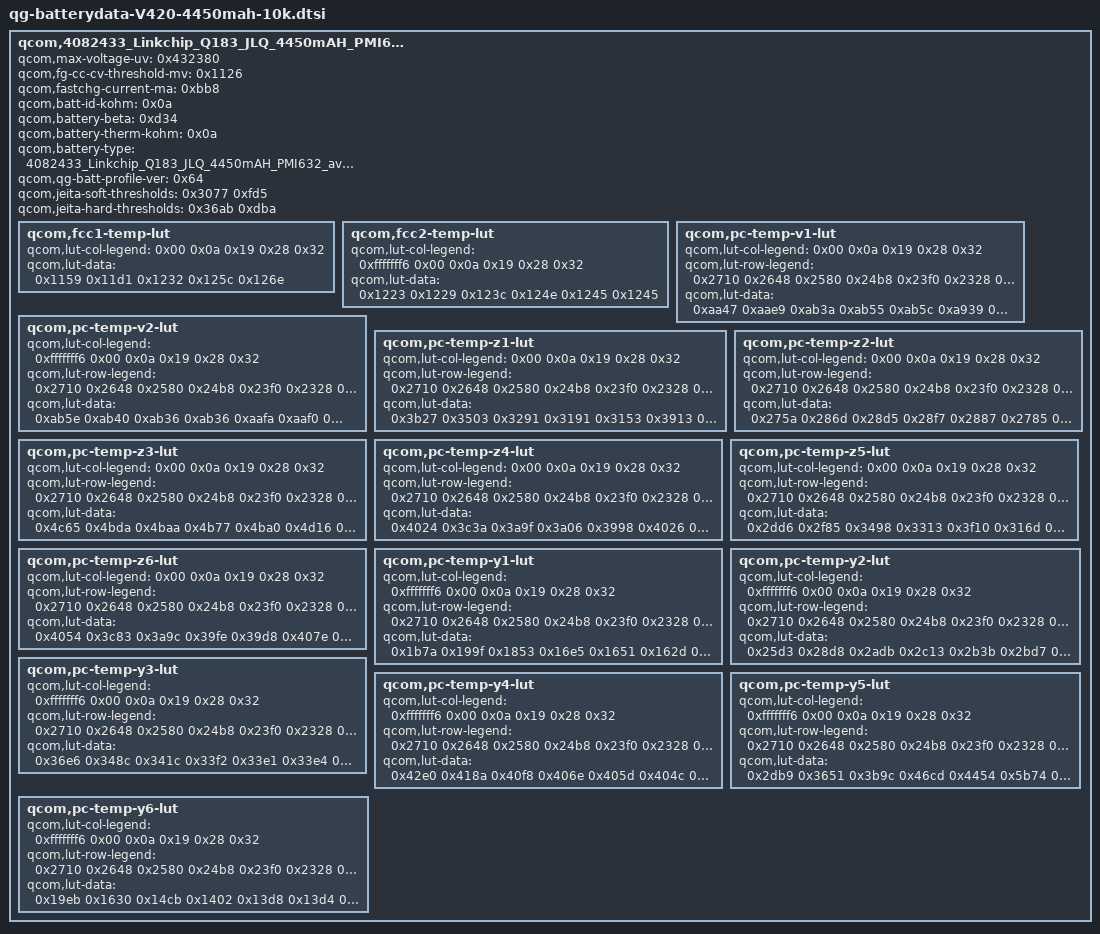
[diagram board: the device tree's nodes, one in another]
qcom,4082433_Linkchip_Q183_JLQ_4450mAH_PMI632 {
	qcom,max-voltage-uv = <0x432380>;
	qcom,fg-cc-cv-threshold-mv = <0x1126>;
	qcom,fastchg-current-ma = <0xbb8>;
	qcom,batt-id-kohm = <0x0a>;
	qcom,battery-beta = <0xd34>;
	qcom,battery-therm-kohm = <0x0a>;
	qcom,battery-type = "4082433_Linkchip_Q183_JLQ_4450mAH_PMI632_averaged_MasterSlave_Jul1th2019";
	qcom,qg-batt-profile-ver = <0x64>;
	qcom,jeita-soft-thresholds = <0x3077 0xfd5>;
	qcom,jeita-hard-thresholds = <0x36ab 0xdba>;

	qcom,fcc1-temp-lut {
		qcom,lut-col-legend = <0x00 0x0a 0x19 0x28 0x32>;
		qcom,lut-data = <0x1159 0x11d1 0x1232 0x125c 0x126e>;
	};

	qcom,fcc2-temp-lut {
		qcom,lut-col-legend = <0xfffffff6 0x00 0x0a 0x19 0x28 0x32>;
		qcom,lut-data = <0x1223 0x1229 0x123c 0x124e 0x1245 0x1245>;
	};

	qcom,pc-temp-v1-lut {
		qcom,lut-col-legend = <0x00 0x0a 0x19 0x28 0x32>;
		qcom,lut-row-legend = <0x2710 0x2648 0x2580 0x24b8 0x23f0 0x2328 0x2260 0x2198 0x20d0 0x2008 0x1f40 0x1e78 0x1db0 0x1ce8 0x1c20 0x1b58 0x1a90 0x19c8 0x1900 0x1838 0x1770 0x16a8 0x15e0 0x1518 0x1450 0x1388 0x12c0 0x11f8 0x1130 0x1068 0xfa0 0xed8 0xe10 0xd48 0xc80 0xbb8 0xaf0 0xa28 0x960 0x898 0x7d0 0x708 0x640 0x578 0x4b0 0x3e8 0x384 0x320 0x2bc 0x258 0x1f4 0x190 0x12c 0xc8 0x64 0x00>;
		qcom,lut-data = <0xaa47 0xaae9 0xab3a 0xab55 0xab5c 0xa939 0xaa1f 0xaa6d 0xaa88 0xaa8d 0xa835 0xa912 0xa98a 0xa9b1 0xa9bb 0xa73e 0xa821 0xa8a3 0xa8d3 0xa8e3 0xa652 0xa731 0xa7b3 0xa7ea 0xa7fe 0xa56e 0xa640 0xa6c3 0xa6fe 0xa715 0xa491 0xa554 0xa5d5 0xa614 0xa62a 0xa3ba 0xa470 0xa4ea 0xa52a 0xa53d 0xa2e6 0xa393 0xa403 0xa442 0xa454 0xa211 0xa2b9 0xa320 0xa35b 0xa36d 0xa149 0xa1e1 0xa23f 0xa277 0xa289 0xa09f 0xa116 0xa161 0xa196 0xa1a8 0x9ff6 0xa069 0xa090 0xa0ba 0xa0ca 0x9f12 0x9fc0 0x9fd8 0x9fe7 0x9ff6 0x9ddd 0x9edd 0x9f1e 0x9f19 0x9f29 0x9cd8 0x9db5 0x9e3d 0x9e4f 0x9e60 0x9c2a 0x9cc3 0x9d46 0x9d87 0x9d9c 0x9b9c 0x9c27 0x9c84 0x9ccb 0x9ce0 0x9b16 0x9ba3 0x9bf3 0x9c22 0x9c33 0x9a9d 0x9b1a 0x9b60 0x9b7a 0x9b88 0x9a26 0x9a94 0x9ab8 0x9abc 0x9aca 0x99ab 0x99ff 0x9a01 0x99ed 0x99f9 0x9931 0x9955 0x9923 0x9921 0x992d 0x98bc 0x98a1 0x981b 0x984d 0x9860 0x984b 0x97dd 0x9768 0x979d 0x97ae 0x97df 0x9715 0x9705 0x9726 0x9730 0x977a 0x9698 0x96b4 0x96c3 0x96c9 0x971a 0x964c 0x9660 0x9660 0x9661 0x96c1 0x9611 0x9612 0x9601 0x95fc 0x966d 0x95df 0x95ca 0x95aa 0x95a0 0x9625 0x95b5 0x9586 0x955d 0x954f 0x95ea 0x958f 0x954a 0x9518 0x9506 0x95b8 0x956d 0x9519 0x94dc 0x94c8 0x958c 0x954c 0x94eb 0x94a6 0x9490 0x9567 0x952f 0x94c0 0x9471 0x9455 0x9540 0x950f 0x9497 0x943f 0x9415 0x9518 0x94e9 0x946b 0x940b 0x93d5 0x94ed 0x94bd 0x943e 0x93d8 0x939a 0x94b4 0x9483 0x9406 0x939c 0x9358 0x946b 0x9430 0x93b2 0x9349 0x9302 0x9411 0x93c6 0x9344 0x92df 0x9297 0x9397 0x934a 0x92cc 0x9269 0x921e 0x9307 0x92b7 0x9244 0x91e0 0x9193 0x926a 0x921c 0x91aa 0x914c 0x90fd 0x91dd 0x918e 0x911c 0x90c2 0x9078 0x9170 0x9129 0x90c7 0x906d 0x9032 0x914a 0x910c 0x90ae 0x9055 0x9018 0x9134 0x90f3 0x909e 0x9044 0x9006 0x9116 0x90dc 0x908c 0x9030 0x8ff3 0x90e6 0x90b0 0x9058 0x8fee 0x8fa3 0x9018 0x8fda 0x8f6a 0x8ee1 0x8e82 0x8e6a 0x8e31 0x8dbb 0x8d20 0x8cbc 0x8c30 0x8bfd 0x8b82 0x8adc 0x8a7b 0x8937 0x8903 0x887d 0x87c7 0x8764 0x84a2 0x847a 0x83e0 0x8308 0x829f 0x7530 0x7530 0x7530 0x7530 0x7530>;
	};

	qcom,pc-temp-v2-lut {
		qcom,lut-col-legend = <0xfffffff6 0x00 0x0a 0x19 0x28 0x32>;
		qcom,lut-row-legend = <0x2710 0x2648 0x2580 0x24b8 0x23f0 0x2328 0x2260 0x2198 0x20d0 0x2008 0x1f40 0x1e78 0x1db0 0x1ce8 0x1c20 0x1b58 0x1a90 0x19c8 0x1900 0x1838 0x1770 0x16a8 0x15e0 0x1518 0x1450 0x1388 0x12c0 0x11f8 0x1130 0x1068 0xfa0 0xed8 0xe10 0xd48 0xc80 0xbb8 0xaf0 0xa28 0x960 0x898 0x7d0 0x708 0x640 0x578 0x4b0 0x3e8 0x384 0x320 0x2bc 0x258 0x1f4 0x190 0x12c 0xc8 0x64 0x00>;
		qcom,lut-data = <0xab5e 0xab40 0xab36 0xab36 0xaafa 0xaaf0 0xa9f9 0xaa01 0xaa27 0xaa38 0xaa07 0xa9fd 0xa8a7 0xa8d6 0xa921 0xa93f 0xa917 0xa90d 0xa769 0xa7c2 0xa824 0xa84b 0xa828 0xa81f 0xa63d 0xa6c2 0xa730 0xa75b 0xa73d 0xa734 0xa523 0xa5c6 0xa63d 0xa66b 0xa651 0xa648 0xa41d 0xa4c6 0xa54b 0xa57c 0xa564 0xa55c 0xa322 0xa3d2 0xa45d 0xa490 0xa478 0xa471 0xa21c 0xa2fa 0xa376 0xa3a9 0xa38f 0xa38a 0xa120 0xa232 0xa294 0xa2c6 0xa2a9 0xa2a6 0xa073 0xa164 0xa1b3 0xa1e3 0xa1c6 0xa1c3 0xa00d 0xa08e 0xa0d3 0xa101 0xa0e7 0xa0e5 0x9f82 0x9fb8 0xa001 0xa029 0xa00c 0xa00a 0x9e07 0x9ef1 0x9f52 0x9f67 0x9f3b 0x9f37 0x9c29 0x9e1e 0x9ea1 0x9ea4 0x9e6d 0x9e68 0x9b14 0x9d01 0x9db2 0x9dc0 0x9da4 0x9da0 0x9a57 0x9b96 0x9c8c 0x9cca 0x9ce0 0x9cdf 0x99a8 0x9a8b 0x9b94 0x9c07 0x9c28 0x9c27 0x9900 0x99e4 0x9acd 0x9b76 0x9b81 0x9b7e 0x985f 0x994f 0x9a10 0x9ada 0x9ad0 0x9acc 0x97bc 0x98a1 0x9949 0x99fa 0x99f7 0x99f6 0x971e 0x97f1 0x9886 0x9905 0x9910 0x9915 0x9691 0x9751 0x97da 0x9838 0x9844 0x984a 0x9610 0x96bf 0x973e 0x9780 0x9787 0x978d 0x95a2 0x9635 0x96b4 0x96e7 0x96ec 0x96f0 0x9548 0x95ac 0x963b 0x966c 0x9670 0x9673 0x94fa 0x9532 0x95d0 0x9600 0x9605 0x9605 0x94b6 0x94d7 0x956b 0x959b 0x95a0 0x959f 0x947a 0x948f 0x950e 0x953f 0x9544 0x9542 0x943f 0x9452 0x94b8 0x94ec 0x94f1 0x94eb 0x9407 0x9420 0x9469 0x94a1 0x94a5 0x949d 0x93d1 0x93f2 0x9421 0x945b 0x945e 0x9455 0x939c 0x93c6 0x93e0 0x9419 0x941f 0x9417 0x9367 0x939a 0x93a6 0x93d9 0x93e0 0x93d8 0x932f 0x936d 0x9379 0x939c 0x9394 0x9386 0x92f4 0x933f 0x9354 0x9361 0x933d 0x9322 0x92b4 0x930b 0x932a 0x9320 0x92e7 0x92bf 0x9273 0x92cd 0x92fa 0x92d8 0x928f 0x925a 0x922f 0x9286 0x92c0 0x928e 0x923a 0x91fc 0x91ec 0x9235 0x9276 0x9245 0x91ee 0x91ac 0x91a7 0x91d9 0x921b 0x91f5 0x91a1 0x915d 0x9165 0x917c 0x91b1 0x9193 0x9140 0x9100 0x911c 0x911c 0x913a 0x911c 0x90cc 0x908d 0x90ce 0x90c2 0x90b9 0x9098 0x9047 0x9009 0x9073 0x9055 0x9050 0x9023 0x8fd7 0x8f9e 0x9001 0x8fe7 0x9008 0x8ffa 0x8fbd 0x8f84 0x8fc0 0x8fb1 0x8fe7 0x8fec 0x8faf 0x8f7a 0x8f78 0x8f68 0x8fca 0x8fda 0x8f9d 0x8f6b 0x8f0e 0x8f18 0x8f9a 0x8fb6 0x8f83 0x8f4e 0x8e74 0x8eb9 0x8f39 0x8f56 0x8f15 0x8eca 0x8d91 0x8df7 0x8e49 0x8e1b 0x8dc3 0x8d68 0x8c2c 0x8c8c 0x8c6b 0x8c32 0x8bd5 0x8b80 0x8a25 0x8a59 0x89f6 0x89bc 0x8960 0x88fb 0x8716 0x8732 0x86ab 0x8653 0x85fc 0x8599 0x8221 0x8207 0x8193 0x815a 0x80cc 0x8057 0x7962 0x77f6 0x77e1 0x76ad 0x7216 0x71f4>;
	};

	qcom,pc-temp-z1-lut {
		qcom,lut-col-legend = <0x00 0x0a 0x19 0x28 0x32>;
		qcom,lut-row-legend = <0x2710 0x2648 0x2580 0x24b8 0x23f0 0x2328 0x2260 0x2198 0x20d0 0x2008 0x1f40 0x1e78 0x1db0 0x1ce8 0x1c20 0x1b58 0x1a90 0x19c8 0x1900 0x1838 0x1770 0x16a8 0x15e0 0x1518 0x1450 0x1388 0x12c0 0x11f8 0x1130 0x1068 0xfa0 0xed8 0xe10 0xd48 0xc80 0xbb8 0xaf0 0xa28 0x960 0x898 0x7d0 0x708 0x640 0x578 0x4b0 0x3e8 0x384 0x320 0x2bc 0x258 0x1f4 0x190 0x12c 0xc8 0x64 0x00>;
		qcom,lut-data = <0x3b27 0x3503 0x3291 0x3191 0x3153 0x3913 0x34d2 0x3268 0x315f 0x311d 0x37b0 0x34c0 0x3248 0x3148 0x310c 0x3762 0x34aa 0x3235 0x313c 0x30fc 0x374a 0x3498 0x322a 0x3131 0x30f5 0x373d 0x3487 0x321f 0x3128 0x30f0 0x3733 0x3479 0x3213 0x3123 0x30ed 0x372b 0x346e 0x320b 0x311f 0x30eb 0x3722 0x3465 0x3205 0x311c 0x30e9 0x3718 0x345d 0x3200 0x3119 0x30e7 0x370d 0x3457 0x31fd 0x3119 0x30e6 0x36ff 0x3450 0x31fb 0x3119 0x30e8 0x36ee 0x3446 0x31f9 0x3119 0x30ec 0x36d9 0x3438 0x31f5 0x3119 0x30ec 0x36bc 0x3426 0x31f0 0x3119 0x30eb 0x36a5 0x340e 0x31ec 0x3119 0x30eb 0x3696 0x3403 0x31e7 0x311a 0x30ee 0x368a 0x3408 0x31e7 0x311b 0x30f1 0x3685 0x3411 0x31ee 0x311d 0x30f1 0x3683 0x3417 0x31f5 0x311f 0x30f1 0x3680 0x341a 0x31f8 0x3120 0x30f1 0x367d 0x3420 0x31fb 0x3121 0x30f2 0x367b 0x342f 0x31fe 0x3122 0x30f4 0x367a 0x343b 0x3200 0x3123 0x30f5 0x367a 0x3439 0x3203 0x3125 0x30f7 0x367a 0x3436 0x3207 0x3129 0x30fa 0x3679 0x3435 0x320a 0x312c 0x30fd 0x3678 0x343e 0x320e 0x3130 0x3100 0x3678 0x3446 0x3212 0x3133 0x3105 0x367b 0x3448 0x3216 0x3137 0x3108 0x3680 0x3449 0x321b 0x313b 0x310b 0x3685 0x344d 0x321f 0x3140 0x310d 0x368b 0x3455 0x3223 0x3143 0x3110 0x3692 0x345e 0x3227 0x3147 0x3114 0x3699 0x3463 0x322c 0x314b 0x3118 0x36a1 0x3467 0x3233 0x314e 0x311c 0x36a9 0x3470 0x3239 0x3152 0x3120 0x36b3 0x3480 0x3240 0x3156 0x3122 0x36be 0x348c 0x3247 0x315a 0x3124 0x36cb 0x3494 0x324c 0x3160 0x3129 0x36d9 0x349b 0x3251 0x3165 0x312f 0x36e5 0x34a6 0x3257 0x316a 0x3133 0x36f2 0x34b3 0x325e 0x316f 0x3136 0x3702 0x34c1 0x3266 0x3173 0x313b 0x3713 0x34cf 0x326f 0x3178 0x3140 0x371d 0x34d1 0x3278 0x317e 0x3140 0x371a 0x34d1 0x3279 0x317f 0x3143 0x3719 0x34d5 0x327c 0x3181 0x3147 0x371e 0x34df 0x3281 0x3185 0x314c 0x372a 0x34ec 0x3289 0x318d 0x3151 0x373c 0x34f8 0x3294 0x3196 0x315a 0x3749 0x3502 0x32a2 0x31a2 0x3166 0x375a 0x3519 0x32b4 0x31b0 0x3174 0x3772 0x353e 0x32d0 0x31c5 0x3187 0x3772 0x353e 0x32d0 0x31c5 0x3187 0x3772 0x353e 0x32d0 0x31c5 0x3187>;
	};

	qcom,pc-temp-z2-lut {
		qcom,lut-col-legend = <0x00 0x0a 0x19 0x28 0x32>;
		qcom,lut-row-legend = <0x2710 0x2648 0x2580 0x24b8 0x23f0 0x2328 0x2260 0x2198 0x20d0 0x2008 0x1f40 0x1e78 0x1db0 0x1ce8 0x1c20 0x1b58 0x1a90 0x19c8 0x1900 0x1838 0x1770 0x16a8 0x15e0 0x1518 0x1450 0x1388 0x12c0 0x11f8 0x1130 0x1068 0xfa0 0xed8 0xe10 0xd48 0xc80 0xbb8 0xaf0 0xa28 0x960 0x898 0x7d0 0x708 0x640 0x578 0x4b0 0x3e8 0x384 0x320 0x2bc 0x258 0x1f4 0x190 0x12c 0xc8 0x64 0x00>;
		qcom,lut-data = <0x275a 0x286d 0x28d5 0x28f7 0x2887 0x2785 0x3043 0x28d7 0x2916 0x28a7 0x27ac 0x282a 0x2904 0x289a 0x2854 0x27cd 0x2819 0x28fb 0x2934 0x2853 0x27eb 0x2808 0x28ec 0x2922 0x28a4 0x2802 0x27f5 0x28de 0x2908 0x2900 0x2816 0x27e5 0x28d5 0x28ea 0x28f9 0x2823 0x27da 0x28ca 0x28ca 0x28d4 0x2822 0x27d2 0x28b7 0x28bb 0x28b9 0x2812 0x27c8 0x28a2 0x28b2 0x28a4 0x2800 0x27b9 0x2899 0x28ab 0x289a 0x27f5 0x27b1 0x2894 0x28a5 0x28a0 0x27e9 0x27eb 0x2893 0x289e 0x28a7 0x27ce 0x2845 0x289c 0x287c 0x2887 0x2795 0x283f 0x28a8 0x2844 0x2827 0x2771 0x27df 0x28b1 0x2840 0x2809 0x276c 0x27ad 0x28b8 0x2872 0x2820 0x2769 0x27c1 0x28c2 0x288f 0x2837 0x2767 0x27e0 0x28cd 0x2885 0x2840 0x2765 0x27f2 0x28db 0x2879 0x2849 0x2763 0x27ff 0x28f3 0x28b4 0x288f 0x275c 0x280e 0x290a 0x294f 0x2957 0x2754 0x2823 0x290a 0x2971 0x299b 0x274f 0x2832 0x2900 0x2916 0x2923 0x274c 0x2832 0x28f2 0x28cf 0x28bc 0x274a 0x2831 0x28d2 0x28c1 0x28bb 0x274e 0x2832 0x28ba 0x28ba 0x28bd 0x2755 0x2838 0x28cf 0x28da 0x28c7 0x275e 0x283e 0x28fc 0x2945 0x28e7 0x2768 0x2839 0x290c 0x296a 0x28f4 0x276f 0x2832 0x2910 0x2933 0x28c6 0x2772 0x282f 0x2914 0x28fb 0x2883 0x2773 0x282e 0x2918 0x28e8 0x2847 0x2777 0x282d 0x291c 0x28dd 0x2810 0x277c 0x282f 0x2922 0x28e3 0x280c 0x2781 0x2832 0x292b 0x2909 0x2834 0x2787 0x2836 0x2935 0x292d 0x2867 0x278d 0x283a 0x293d 0x2947 0x28a5 0x2794 0x2840 0x2947 0x2960 0x28e0 0x279e 0x284e 0x2959 0x297b 0x28fc 0x27a6 0x285d 0x296c 0x2995 0x290e 0x27aa 0x2863 0x2970 0x29a3 0x2925 0x27b0 0x2868 0x2970 0x29ab 0x2942 0x27fa 0x2876 0x2976 0x299d 0x296a 0x2864 0x28d7 0x2993 0x296f 0x2983 0x288b 0x29d5 0x29cd 0x2957 0x2923 0x2863 0x2a24 0x2995 0x295e 0x2928 0x264f 0x2a69 0x29d4 0x2982 0x291f 0x270f 0x2a68 0x2a9d 0x299e 0x2978 0x3a60 0x2aa5 0x2ab1 0x29cb 0x2987 0x26f9 0x2a6c 0x2a79 0x2984 0x28cc 0x25ef 0x29e9 0x2a8f 0x291c 0x2865 0x271b 0x291f 0x2a25 0x28d0 0x2829 0x264c 0x2839 0x29df 0x289b 0x27e3 0x264c 0x2839 0x29df 0x289b 0x27e3 0x264c 0x2839 0x29df 0x289b 0x27e3>;
	};

	qcom,pc-temp-z3-lut {
		qcom,lut-col-legend = <0x00 0x0a 0x19 0x28 0x32>;
		qcom,lut-row-legend = <0x2710 0x2648 0x2580 0x24b8 0x23f0 0x2328 0x2260 0x2198 0x20d0 0x2008 0x1f40 0x1e78 0x1db0 0x1ce8 0x1c20 0x1b58 0x1a90 0x19c8 0x1900 0x1838 0x1770 0x16a8 0x15e0 0x1518 0x1450 0x1388 0x12c0 0x11f8 0x1130 0x1068 0xfa0 0xed8 0xe10 0xd48 0xc80 0xbb8 0xaf0 0xa28 0x960 0x898 0x7d0 0x708 0x640 0x578 0x4b0 0x3e8 0x384 0x320 0x2bc 0x258 0x1f4 0x190 0x12c 0xc8 0x64 0x00>;
		qcom,lut-data = <0x4c65 0x4bda 0x4baa 0x4b77 0x4ba0 0x4d16 0x4be0 0x4bcc 0x4b96 0x4b90 0x4d85 0x4c92 0x4bf1 0x4ba3 0x4b99 0x4d91 0x4cb1 0x4c01 0x4bc0 0x4baa 0x4d85 0x4cc3 0x4c09 0x4bc6 0x4bb5 0x4d73 0x4cd2 0x4c0b 0x4bc8 0x4bbb 0x4d4b 0x4cda 0x4c09 0x4bc8 0x4bc0 0x4d20 0x4cd6 0x4c08 0x4bc7 0x4bc3 0x4d1a 0x4ccd 0x4c07 0x4bc7 0x4bc4 0x4d1e 0x4cc7 0x4c06 0x4bc8 0x4bc5 0x4d21 0x4cc4 0x4c05 0x4bc8 0x4bc5 0x4d18 0x4cc0 0x4c05 0x4bc6 0x4bc4 0x4d0b 0x4cb9 0x4c04 0x4bc1 0x4bc0 0x4d16 0x4cb1 0x4bf2 0x4bbc 0x4bba 0x4d58 0x4cb0 0x4be0 0x4bb5 0x4bb0 0x4d80 0x4cb0 0x4be5 0x4bb4 0x4bab 0x4d70 0x4caf 0x4bf4 0x4bb5 0x4ba9 0x4d54 0x4c99 0x4bf7 0x4bb5 0x4ba7 0x4d43 0x4c7d 0x4be9 0x4bb1 0x4ba3 0x4d36 0x4c77 0x4be1 0x4bac 0x4b9e 0x4d31 0x4c74 0x4be5 0x4baf 0x4ba0 0x4d37 0x4c74 0x4bed 0x4bb8 0x4ba6 0x4d44 0x4c85 0x4bf2 0x4bba 0x4ba8 0x4d51 0x4c98 0x4bf6 0x4bb0 0x4b9f 0x4d60 0x4c9b 0x4bf6 0x4ba7 0x4b97 0x4d6b 0x4c9d 0x4bec 0x4ba3 0x4b9a 0x4d70 0x4c9e 0x4be4 0x4ba1 0x4ba2 0x4d74 0x4c9e 0x4be4 0x4ba9 0x4bae 0x4d74 0x4c9e 0x4be6 0x4bc3 0x4bc3 0x4d73 0x4c9b 0x4bea 0x4bce 0x4bcb 0x4d71 0x4c96 0x4bf3 0x4bcd 0x4bc6 0x4d6c 0x4c92 0x4bf7 0x4bcc 0x4bbf 0x4d62 0x4c8e 0x4bf7 0x4bc9 0x4bb7 0x4d58 0x4c89 0x4bf6 0x4bc2 0x4bae 0x4d4b 0x4c82 0x4bf5 0x4bbc 0x4ba7 0x4d3e 0x4c7a 0x4bf3 0x4bb6 0x4ba1 0x4d32 0x4c77 0x4bf0 0x4bb1 0x4b9e 0x4d25 0x4c76 0x4bed 0x4bae 0x4b9c 0x4d15 0x4c74 0x4bea 0x4bac 0x4b9b 0x4cff 0x4c6c 0x4be7 0x4ba9 0x4b9b 0x4ceb 0x4c64 0x4be5 0x4ba7 0x4b9c 0x4ce0 0x4c61 0x4be2 0x4ba7 0x4b9d 0x4cd1 0x4c60 0x4bdf 0x4ba8 0x4ba1 0x4cab 0x4c55 0x4bdd 0x4ba8 0x4ba5 0x4c09 0x4c29 0x4bd7 0x4ba3 0x4ba6 0x4b95 0x4bdc 0x4bbb 0x4b97 0x4b8c 0x4b92 0x4b91 0x4bb0 0x4b93 0x4b86 0x4b44 0x4b7d 0x4b90 0x4b8d 0x4b85 0x4b41 0x4b78 0x4b79 0x4b8a 0x4b7a 0x4b39 0x4b73 0x4b79 0x4b85 0x4b7e 0x4b41 0x4b73 0x4b83 0x4b8d 0x4b94 0x4b46 0x4b75 0x4b85 0x4b98 0x4b9c 0x4ba4 0x4b7b 0x4b84 0x4b9b 0x4b9a 0x4bae 0x4b7b 0x4b81 0x4b9b 0x4b98 0x4bae 0x4b7b 0x4b81 0x4b9b 0x4b98 0x4bae 0x4b7b 0x4b81 0x4b9b 0x4b98>;
	};

	qcom,pc-temp-z4-lut {
		qcom,lut-col-legend = <0x00 0x0a 0x19 0x28 0x32>;
		qcom,lut-row-legend = <0x2710 0x2648 0x2580 0x24b8 0x23f0 0x2328 0x2260 0x2198 0x20d0 0x2008 0x1f40 0x1e78 0x1db0 0x1ce8 0x1c20 0x1b58 0x1a90 0x19c8 0x1900 0x1838 0x1770 0x16a8 0x15e0 0x1518 0x1450 0x1388 0x12c0 0x11f8 0x1130 0x1068 0xfa0 0xed8 0xe10 0xd48 0xc80 0xbb8 0xaf0 0xa28 0x960 0x898 0x7d0 0x708 0x640 0x578 0x4b0 0x3e8 0x384 0x320 0x2bc 0x258 0x1f4 0x190 0x12c 0xc8 0x64 0x00>;
		qcom,lut-data = <0x4024 0x3c3a 0x3a9f 0x3a06 0x3998 0x4026 0x3c6b 0x3a77 0x39fa 0x39da 0x4026 0x3c95 0x3a65 0x39e4 0x39c8 0x3ff9 0x3c08 0x3a7c 0x3a03 0x39ee 0x3f19 0x3b8c 0x3a41 0x39ee 0x39df 0x3e49 0x3b27 0x3a15 0x39d5 0x39c7 0x3dd6 0x3ad2 0x39f6 0x39c4 0x39b6 0x3d77 0x3a94 0x39dd 0x39b5 0x39a7 0x3d19 0x3a63 0x39c8 0x39a6 0x3998 0x3cbd 0x3a3e 0x39b5 0x3997 0x398a 0x3c67 0x3a23 0x39a6 0x398a 0x397d 0x3c16 0x3a06 0x3998 0x397e 0x3972 0x3bca 0x39d5 0x398e 0x3974 0x3969 0x3b86 0x39a6 0x3987 0x3971 0x3968 0x3b49 0x39a2 0x3982 0x396f 0x3968 0x3b15 0x39b1 0x397d 0x396b 0x3967 0x3aeb 0x39b9 0x3978 0x3964 0x3962 0x3ac7 0x39b2 0x3971 0x395d 0x395c 0x3aa9 0x39a6 0x3968 0x3958 0x3957 0x3a8f 0x3999 0x3963 0x3955 0x3953 0x3a74 0x398a 0x3964 0x395a 0x3957 0x3a56 0x3985 0x3968 0x396d 0x396b 0x3a38 0x3988 0x3982 0x3988 0x3987 0x3a1d 0x398e 0x39cd 0x39bd 0x39b7 0x3a04 0x39ae 0x39eb 0x39dd 0x39d7 0x39f2 0x39ec 0x39e3 0x39d8 0x39cd 0x39e5 0x39fd 0x39d6 0x39cc 0x39b3 0x39db 0x39f2 0x39c8 0x39b6 0x3998 0x39d5 0x39e4 0x39b7 0x398e 0x3978 0x39d2 0x39d6 0x39a6 0x3976 0x3967 0x39cf 0x39c6 0x3995 0x396c 0x3962 0x39cd 0x39b8 0x3987 0x3965 0x395f 0x39cc 0x39ab 0x397d 0x3961 0x395b 0x39c9 0x399f 0x3975 0x395d 0x3957 0x39c6 0x3995 0x396f 0x395d 0x3958 0x39c2 0x398b 0x396b 0x395f 0x395c 0x39bf 0x3984 0x3968 0x3960 0x395f 0x39bb 0x397d 0x3966 0x3960 0x395e 0x39bc 0x397a 0x3964 0x395f 0x395e 0x39c1 0x397a 0x3966 0x3962 0x3960 0x39c5 0x397a 0x3969 0x3969 0x3966 0x39c6 0x3978 0x3968 0x396a 0x3966 0x39c7 0x3974 0x3962 0x3962 0x395e 0x39d4 0x3976 0x395e 0x3961 0x395d 0x3a27 0x397d 0x3958 0x3960 0x395c 0x3a64 0x3994 0x3948 0x3948 0x3948 0x3a67 0x39e4 0x394d 0x3944 0x3947 0x3ab4 0x39f5 0x3965 0x393a 0x3939 0x3aae 0x39f6 0x3976 0x392d 0x392f 0x3aa4 0x39f5 0x3972 0x3930 0x3926 0x3a9d 0x39fa 0x3978 0x3944 0x3934 0x3ab2 0x3a03 0x397e 0x3945 0x393c 0x3a66 0x3a08 0x3986 0x3947 0x3942 0x3a79 0x3a19 0x3990 0x394d 0x3949 0x3a79 0x3a19 0x3990 0x394d 0x3949 0x3a79 0x3a19 0x3990 0x394d 0x3949>;
	};

	qcom,pc-temp-z5-lut {
		qcom,lut-col-legend = <0x00 0x0a 0x19 0x28 0x32>;
		qcom,lut-row-legend = <0x2710 0x2648 0x2580 0x24b8 0x23f0 0x2328 0x2260 0x2198 0x20d0 0x2008 0x1f40 0x1e78 0x1db0 0x1ce8 0x1c20 0x1b58 0x1a90 0x19c8 0x1900 0x1838 0x1770 0x16a8 0x15e0 0x1518 0x1450 0x1388 0x12c0 0x11f8 0x1130 0x1068 0xfa0 0xed8 0xe10 0xd48 0xc80 0xbb8 0xaf0 0xa28 0x960 0x898 0x7d0 0x708 0x640 0x578 0x4b0 0x3e8 0x384 0x320 0x2bc 0x258 0x1f4 0x190 0x12c 0xc8 0x64 0x00>;
		qcom,lut-data = <0x2dd6 0x2f85 0x3498 0x3313 0x3f10 0x316d 0x301d 0x3ab9 0x3b52 0x3da1 0x33ff 0x38f6 0x426f 0x40d6 0x432c 0x3522 0x3b39 0x424c 0x46c7 0x4631 0x35d5 0x3dd5 0x4523 0x48e0 0x4a44 0x3616 0x415a 0x4754 0x49d7 0x4d97 0x35ca 0x4448 0x48bd 0x4a46 0x50ee 0x355e 0x45d7 0x4a1b 0x4a92 0x5418 0x358b 0x46fd 0x4b94 0x4b72 0x5743 0x36a8 0x48a2 0x4d33 0x4d92 0x5a67 0x3754 0x4b02 0x4fbf 0x4fd6 0x5dab 0x3744 0x4d87 0x53a6 0x5283 0x621e 0x372e 0x4f9c 0x551e 0x5455 0x65b6 0x3874 0x51ec 0x504b 0x540b 0x6368 0x3e7e 0x5715 0x4b39 0x534e 0x5bb4 0x422b 0x61a3 0x5249 0x5440 0x5981 0x412f 0x66a6 0x6391 0x5b27 0x5d8e 0x3fbd 0x5eb8 0x679f 0x6086 0x61d9 0x3f84 0x551a 0x62d1 0x61f1 0x639f 0x3fb7 0x55c1 0x5f9b 0x6359 0x653b 0x4017 0x5ce2 0x6ef0 0x6dbe 0x6b15 0x42a2 0x69da 0x84a0 0x8396 0x77ff 0x47c0 0x998f 0x872b 0x8686 0x7b10 0x4df7 0xc355 0x86f2 0x699e 0x61ac 0x56cc 0xc541 0x854d 0x5088 0x4a47 0x608e 0xc557 0x6f6b 0x47de 0x46db 0x6ae9 0xc403 0x5af9 0x42d9 0x4525 0x7593 0xb72c 0x597a 0x4651 0x4995 0x7f68 0xa87a 0x58f3 0x5528 0x5e71 0x899f 0x9f18 0x5a9c 0x61ef 0x6c47 0x8e77 0x9742 0x65d9 0x6b66 0x71b1 0x8ba1 0x91fd 0x71aa 0x7347 0x745f 0x8587 0x8e75 0x79f6 0x7a24 0x72d0 0x7ec0 0x8ac9 0x81da 0x7f73 0x6f81 0x75e6 0x84d0 0x8b72 0x80b8 0x6f75 0x6dc8 0x7fa4 0x95d0 0x811d 0x7319 0x6803 0x8031 0x98b6 0x812f 0x7550 0x62e3 0x846c 0x9765 0x7fb8 0x759f 0x5cc9 0x8636 0x9520 0x7cd0 0x75c3 0x5538 0x8062 0x911a 0x7590 0x7209 0x50be 0x7a11 0x8b1a 0x6ab8 0x691d 0x500e 0x79cd 0x84fc 0x6852 0x680f 0x4f4c 0x7a1e 0x7ebd 0x688b 0x7035 0x487e 0x70ac 0x7cf6 0x66a6 0x73b2 0x3858 0x58cf 0x79ca 0x603b 0x73e3 0x3033 0x4182 0x63a7 0x5cbd 0x5678 0x2fb9 0x332d 0x5614 0x578c 0x4e85 0x2c38 0x3085 0x3f15 0x569e 0x5427 0x2c32 0x300b 0x36cd 0x5ae8 0x515c 0x2c40 0x2fe3 0x3784 0x53ce 0x6437 0x2c90 0x304b 0x39a8 0x4b7d 0x626a 0x2ca3 0x3000 0x38c8 0x4d08 0x5b54 0x3011 0x2fef 0x36f8 0x4b41 0x50f9 0x2f76 0x2f20 0x3546 0x4628 0x45ba 0x2f76 0x2f20 0x3546 0x4628 0x45ba 0x2f76 0x2f20 0x3546 0x4628 0x45ba>;
	};

	qcom,pc-temp-z6-lut {
		qcom,lut-col-legend = <0x00 0x0a 0x19 0x28 0x32>;
		qcom,lut-row-legend = <0x2710 0x2648 0x2580 0x24b8 0x23f0 0x2328 0x2260 0x2198 0x20d0 0x2008 0x1f40 0x1e78 0x1db0 0x1ce8 0x1c20 0x1b58 0x1a90 0x19c8 0x1900 0x1838 0x1770 0x16a8 0x15e0 0x1518 0x1450 0x1388 0x12c0 0x11f8 0x1130 0x1068 0xfa0 0xed8 0xe10 0xd48 0xc80 0xbb8 0xaf0 0xa28 0x960 0x898 0x7d0 0x708 0x640 0x578 0x4b0 0x3e8 0x384 0x320 0x2bc 0x258 0x1f4 0x190 0x12c 0xc8 0x64 0x00>;
		qcom,lut-data = <0x4054 0x3c83 0x3a9c 0x39fe 0x39d8 0x407e 0x3c83 0x3a8f 0x39fe 0x39e2 0x4088 0x3ccd 0x3a95 0x39f9 0x39dc 0x406c 0x3c93 0x3aa1 0x3a12 0x39f3 0x3fdf 0x3c5c 0x3a89 0x3a0a 0x39f0 0x3f55 0x3c2b 0x3a74 0x3a00 0x39eb 0x3efa 0x3bfe 0x3a63 0x39f8 0x39e6 0x3eae 0x3bd7 0x3a55 0x39f0 0x39e0 0x3e70 0x3bb5 0x3a49 0x39ea 0x39db 0x3e3e 0x3b9b 0x3a3f 0x39e4 0x39d5 0x3e0e 0x3b88 0x3a37 0x39de 0x39cf 0x3dd4 0x3b74 0x3a31 0x39d7 0x39ca 0x3d9e 0x3b55 0x3a2a 0x39d1 0x39c6 0x3d81 0x3b37 0x3a1b 0x39cc 0x39c0 0x3d70 0x3b2d 0x3a0f 0x39c8 0x39bb 0x3d5d 0x3b2a 0x3a10 0x39c5 0x39b7 0x3d3a 0x3b25 0x3a13 0x39c2 0x39b4 0x3d14 0x3b17 0x3a13 0x39c0 0x39b1 0x3cf9 0x3b08 0x3a09 0x39bb 0x39ac 0x3ce6 0x3b00 0x3a03 0x39b7 0x39a8 0x3cd7 0x3afa 0x3a05 0x39bb 0x39aa 0x3ccc 0x3af9 0x3a0c 0x39c8 0x39b7 0x3cc3 0x3b03 0x3a1c 0x39d5 0x39c5 0x3cbe 0x3b14 0x3a3f 0x39e7 0x39d5 0x3cba 0x3b2a 0x3a4c 0x39f1 0x39df 0x3cb7 0x3b43 0x3a45 0x39ee 0x39dc 0x3cb3 0x3b49 0x3a3c 0x39e8 0x39d6 0x3cb0 0x3b48 0x3a36 0x39e4 0x39d3 0x3cae 0x3b46 0x3a31 0x39e1 0x39d1 0x3cad 0x3b40 0x3a2e 0x39de 0x39ce 0x3cac 0x3b36 0x3a2b 0x39da 0x39ca 0x3cab 0x3b30 0x3a29 0x39d6 0x39c5 0x3caa 0x3b2c 0x3a25 0x39d3 0x39c0 0x3ca8 0x3b28 0x3a22 0x39cf 0x39b9 0x3ca3 0x3b21 0x3a20 0x39cc 0x39b7 0x3c9f 0x3b1a 0x3a1f 0x39ca 0x39b6 0x3c9c 0x3b1a 0x3a1e 0x39c8 0x39b5 0x3c9a 0x3b1d 0x3a1c 0x39c6 0x39b3 0x3c99 0x3b1e 0x3a1b 0x39c5 0x39b3 0x3c9a 0x3b1e 0x3a1c 0x39c6 0x39b4 0x3c9a 0x3b1f 0x3a1d 0x39c9 0x39b8 0x3c9f 0x3b21 0x3a1d 0x39c9 0x39b9 0x3ca3 0x3b27 0x3a1b 0x39c8 0x39b9 0x3ca2 0x3b27 0x3a1b 0x39c7 0x39ba 0x3c8b 0x3b22 0x3a19 0x39c6 0x39bb 0x3c76 0x3b0a 0x3a06 0x39b6 0x39a6 0x3c75 0x3b06 0x3a03 0x39b2 0x39a2 0x3c72 0x3b07 0x39fe 0x39ac 0x399c 0x3c72 0x3b0a 0x39fb 0x39a5 0x3992 0x3c76 0x3b0d 0x39fc 0x39a5 0x3992 0x3c7f 0x3b15 0x3a07 0x39b3 0x39a5 0x3c93 0x3b20 0x3a0f 0x39bc 0x39b0 0x3cac 0x3b30 0x3a16 0x39c2 0x39b4 0x3cce 0x3b4a 0x3a22 0x39ca 0x39ba 0x3cce 0x3b4a 0x3a22 0x39ca 0x39ba 0x3cce 0x3b4a 0x3a22 0x39ca 0x39ba>;
	};

	qcom,pc-temp-y1-lut {
		qcom,lut-col-legend = <0xfffffff6 0x00 0x0a 0x19 0x28 0x32>;
		qcom,lut-row-legend = <0x2710 0x2648 0x2580 0x24b8 0x23f0 0x2328 0x2260 0x2198 0x20d0 0x2008 0x1f40 0x1e78 0x1db0 0x1ce8 0x1c20 0x1b58 0x1a90 0x19c8 0x1900 0x1838 0x1770 0x16a8 0x15e0 0x1518 0x1450 0x1388 0x12c0 0x11f8 0x1130 0x1068 0xfa0 0xed8 0xe10 0xd48 0xc80 0xbb8 0xaf0 0xa28 0x960 0x898 0x7d0 0x708 0x640 0x578 0x4b0 0x3e8 0x384 0x320 0x2bc 0x258 0x1f4 0x190 0x12c 0xc8 0x64 0x00>;
		qcom,lut-data = <0x1b7a 0x199f 0x1853 0x16e5 0x1651 0x162d 0x1b7b 0x19a4 0x1850 0x16e5 0x1651 0x162c 0x1b7c 0x19a8 0x184d 0x16e5 0x1651 0x162a 0x1b7d 0x19ab 0x184a 0x16e5 0x1650 0x1629 0x1b7e 0x19ac 0x1848 0x16e5 0x1650 0x1628 0x1b80 0x19ac 0x1846 0x16e5 0x164f 0x1627 0x1b81 0x19ab 0x1845 0x16e3 0x164e 0x1626 0x1b83 0x19a9 0x1845 0x16e2 0x164d 0x1626 0x1b91 0x19ac 0x1845 0x16e1 0x164c 0x1625 0x1bad 0x19b1 0x1846 0x16e0 0x164b 0x1624 0x1bb1 0x19b2 0x1846 0x16df 0x164a 0x1624 0x1b99 0x19b1 0x1845 0x16de 0x1649 0x1624 0x1b89 0x19b0 0x1844 0x16dd 0x1649 0x1624 0x1b8c 0x19b2 0x1843 0x16db 0x164a 0x1624 0x1b91 0x19b4 0x1842 0x16d9 0x164b 0x1625 0x1b93 0x19be 0x1843 0x16dd 0x164b 0x1625 0x1b94 0x19d5 0x1849 0x16e8 0x164b 0x1625 0x1b95 0x19dd 0x184d 0x16ea 0x164c 0x1626 0x1b94 0x19d2 0x1851 0x16e4 0x164c 0x1627 0x1b94 0x19c7 0x1852 0x16e1 0x164d 0x1628 0x1b94 0x19c2 0x1851 0x16e2 0x164d 0x1629 0x1b94 0x19bf 0x184e 0x16e4 0x164d 0x1629 0x1b94 0x19bf 0x184e 0x16e5 0x164e 0x162a 0x1b94 0x19c1 0x184e 0x16e6 0x1651 0x162b 0x1b93 0x19c3 0x184e 0x16e7 0x1653 0x162c 0x1b93 0x19c5 0x1850 0x16e9 0x1655 0x162e 0x1b92 0x19c6 0x1852 0x16ea 0x1656 0x1630 0x1b91 0x19c5 0x1852 0x16ec 0x1657 0x1632 0x1b91 0x19c3 0x1851 0x16ef 0x1658 0x1633 0x1b91 0x19c2 0x1852 0x16f1 0x165a 0x1635 0x1b90 0x19c1 0x1855 0x16f4 0x165c 0x1638 0x1b8f 0x19c1 0x1858 0x16f6 0x165f 0x163a 0x1b8e 0x19c1 0x1857 0x16f8 0x1662 0x163d 0x1b8c 0x19c1 0x1856 0x16fb 0x1666 0x1640 0x1b8b 0x19c1 0x1857 0x16fe 0x1668 0x1642 0x1b8b 0x19c2 0x185c 0x1700 0x166a 0x1644 0x1b8b 0x19c3 0x185f 0x1703 0x166c 0x1645 0x1b8a 0x19c5 0x1860 0x1705 0x166e 0x1647 0x1b89 0x19c7 0x1861 0x1708 0x1670 0x1649 0x1b88 0x19c8 0x1864 0x1709 0x1672 0x164b 0x1b88 0x19c9 0x1866 0x170b 0x1674 0x164e 0x1b88 0x19cb 0x1868 0x170e 0x1676 0x1650 0x1b88 0x19ca 0x186d 0x1712 0x1679 0x1651 0x1b99 0x19d4 0x1870 0x1717 0x167d 0x1655 0x1bcb 0x19d8 0x1879 0x171c 0x1681 0x1659 0x1b9f 0x19d9 0x1879 0x1724 0x1686 0x165e 0x1ba2 0x19de 0x1880 0x1726 0x1687 0x165e 0x1ba4 0x19e3 0x187e 0x1727 0x1688 0x165e 0x1ba6 0x19df 0x1882 0x1728 0x1687 0x165d 0x1ba8 0x19e5 0x1884 0x1729 0x1689 0x165f 0x1bad 0x19ea 0x188a 0x1731 0x168d 0x1663 0x1bb4 0x19f0 0x1890 0x173a 0x1695 0x166a 0x1bd0 0x19fb 0x189f 0x174a 0x16a0 0x1676 0x1bff 0x1a0f 0x18b2 0x175f 0x16ae 0x1682 0x1bff 0x1a0f 0x18b2 0x175f 0x16ae 0x1682 0x1bff 0x1a0f 0x18b2 0x175f 0x16ae 0x1682>;
	};

	qcom,pc-temp-y2-lut {
		qcom,lut-col-legend = <0xfffffff6 0x00 0x0a 0x19 0x28 0x32>;
		qcom,lut-row-legend = <0x2710 0x2648 0x2580 0x24b8 0x23f0 0x2328 0x2260 0x2198 0x20d0 0x2008 0x1f40 0x1e78 0x1db0 0x1ce8 0x1c20 0x1b58 0x1a90 0x19c8 0x1900 0x1838 0x1770 0x16a8 0x15e0 0x1518 0x1450 0x1388 0x12c0 0x11f8 0x1130 0x1068 0xfa0 0xed8 0xe10 0xd48 0xc80 0xbb8 0xaf0 0xa28 0x960 0x898 0x7d0 0x708 0x640 0x578 0x4b0 0x3e8 0x384 0x320 0x2bc 0x258 0x1f4 0x190 0x12c 0xc8 0x64 0x00>;
		qcom,lut-data = <0x25d3 0x28d8 0x2adb 0x2c13 0x2b3b 0x2bd7 0x25c9 0x28ed 0x2abd 0x2bfd 0x2b51 0x2ba6 0x25c5 0x2901 0x2a9f 0x2be5 0x2b5a 0x2b77 0x25c5 0x2914 0x2a84 0x2bcb 0x2b59 0x2b4c 0x25c9 0x2925 0x2a6d 0x2baf 0x2b51 0x2b26 0x25ce 0x2933 0x2a5b 0x2b92 0x2b45 0x2b05 0x25db 0x2941 0x2a4c 0x2b70 0x2b24 0x2ae9 0x25e5 0x294a 0x2a41 0x2b51 0x2b01 0x2ad2 0x25e2 0x293d 0x2a39 0x2b3b 0x2aef 0x2abf 0x25dd 0x2921 0x2a33 0x2b29 0x2ae1 0x2aaf 0x25dd 0x2932 0x2a32 0x2b22 0x2ad2 0x2aa5 0x25e8 0x29cd 0x2a38 0x2b1f 0x2ac1 0x2aa0 0x25ef 0x2a30 0x2a43 0x2b1b 0x2aba 0x2a99 0x25e8 0x2a23 0x2a73 0x2b10 0x2aff 0x2a88 0x25da 0x2a12 0x2aac 0x2b05 0x2b4e 0x2a78 0x25d2 0x2a19 0x2ab8 0x2b16 0x2b48 0x2a83 0x25cb 0x2a38 0x2abc 0x2b4b 0x2b2a 0x2aab 0x25c9 0x2a56 0x2ac7 0x2b87 0x2b2c 0x2ad7 0x25c8 0x2a73 0x2aea 0x2bd9 0x2b98 0x2b0e 0x25c8 0x2a8a 0x2b0f 0x2c06 0x2bff 0x2b37 0x25c7 0x2a99 0x2b26 0x2bfe 0x2c2a 0x2b44 0x25c5 0x2aa3 0x2b38 0x2bf4 0x2c45 0x2b4f 0x25c4 0x2aa8 0x2b4c 0x2bf9 0x2c39 0x2b68 0x25c3 0x2aaa 0x2b60 0x2c13 0x2c01 0x2b98 0x25c3 0x2aad 0x2b73 0x2c2c 0x2be9 0x2bc7 0x25c2 0x2ac4 0x2b84 0x2c46 0x2bf5 0x2bf6 0x25c2 0x2ade 0x2b90 0x2c5b 0x2c0b 0x2c18 0x25c1 0x2ae3 0x2b95 0x2c67 0x2c2f 0x2c21 0x25c0 0x2ae5 0x2b98 0x2c6f 0x2c60 0x2c26 0x25bf 0x2ae4 0x2b9a 0x2c7c 0x2c7a 0x2c3a 0x25be 0x2acb 0x2b9b 0x2c8d 0x2c87 0x2c79 0x25be 0x2a98 0x2b9e 0x2c95 0x2c94 0x2c9b 0x25bd 0x2912 0x2bae 0x2c96 0x2ca4 0x2c9a 0x25bc 0x2693 0x2bc2 0x2c96 0x2caf 0x2c96 0x25bb 0x25fd 0x2bb6 0x2c95 0x2caa 0x2c88 0x25bb 0x25e9 0x2b80 0x2c91 0x2c94 0x2c61 0x25ba 0x25dc 0x2b50 0x2c83 0x2c7a 0x2c3c 0x25ba 0x25d2 0x2b2e 0x2c4a 0x2c59 0x2c12 0x25b9 0x25ca 0x2b0b 0x2c26 0x2c37 0x2bfb 0x25b9 0x25c5 0x2ade 0x2c34 0x2c18 0x2c08 0x25b9 0x25c2 0x2aaa 0x2c40 0x2c08 0x2c15 0x25b9 0x25bf 0x2a6e 0x2c2f 0x2c26 0x2bef 0x25b8 0x25bd 0x2a19 0x2c24 0x2bf8 0x2bb8 0x25b8 0x25bd 0x29fe 0x2c0c 0x2c1c 0x2c00 0x25b8 0x25bb 0x298e 0x2bd9 0x2bfb 0x2ba2 0x25b8 0x25ba 0x2942 0x2b9a 0x2bd2 0x2b31 0x25b7 0x25b9 0x291f 0x2b91 0x2bb6 0x2ad8 0x25b7 0x25b9 0x28f8 0x2b8c 0x2b92 0x2b2a 0x25b7 0x25b8 0x28e5 0x2b7c 0x2baf 0x2b71 0x25b7 0x25b8 0x28d3 0x2b73 0x2ba1 0x2b39 0x25b7 0x25b7 0x28a7 0x2b47 0x2b68 0x2a96 0x25b6 0x25b7 0x2672 0x2b03 0x2ae8 0x2a91 0x25b5 0x25b6 0x25d8 0x2aa5 0x2ae7 0x2a2b 0x25b3 0x25b5 0x25c3 0x2a43 0x2a49 0x29cd 0x25b3 0x25b5 0x25c3 0x2a43 0x2a49 0x29cd 0x25b3 0x25b5 0x25c3 0x2a43 0x2a49 0x29cd>;
	};

	qcom,pc-temp-y3-lut {
		qcom,lut-col-legend = <0xfffffff6 0x00 0x0a 0x19 0x28 0x32>;
		qcom,lut-row-legend = <0x2710 0x2648 0x2580 0x24b8 0x23f0 0x2328 0x2260 0x2198 0x20d0 0x2008 0x1f40 0x1e78 0x1db0 0x1ce8 0x1c20 0x1b58 0x1a90 0x19c8 0x1900 0x1838 0x1770 0x16a8 0x15e0 0x1518 0x1450 0x1388 0x12c0 0x11f8 0x1130 0x1068 0xfa0 0xed8 0xe10 0xd48 0xc80 0xbb8 0xaf0 0xa28 0x960 0x898 0x7d0 0x708 0x640 0x578 0x4b0 0x3e8 0x384 0x320 0x2bc 0x258 0x1f4 0x190 0x12c 0xc8 0x64 0x00>;
		qcom,lut-data = <0x36e6 0x348c 0x341c 0x33f2 0x33e1 0x33e4 0x36b0 0x348f 0x3421 0x33f0 0x33e2 0x33e3 0x367c 0x3493 0x3426 0x33ef 0x33e3 0x33e2 0x364a 0x3498 0x342b 0x33ed 0x33e4 0x33e0 0x361b 0x349b 0x3430 0x33ec 0x33e5 0x33df 0x35ef 0x349c 0x3432 0x33eb 0x33e5 0x33df 0x35c6 0x349c 0x3434 0x33eb 0x33e5 0x33df 0x359f 0x349c 0x3435 0x33ea 0x33e5 0x33df 0x3571 0x34a3 0x3436 0x33ee 0x33e6 0x33e1 0x3544 0x34b1 0x3437 0x33f5 0x33e6 0x33e4 0x352e 0x34b3 0x3437 0x33f7 0x33e7 0x33e5 0x3524 0x34a7 0x3437 0x33f7 0x33e7 0x33e5 0x351a 0x3497 0x3436 0x33f7 0x33e7 0x33e5 0x3508 0x3485 0x3439 0x33fb 0x33e8 0x33e5 0x34f2 0x3473 0x343b 0x3400 0x33e9 0x33e6 0x34dd 0x3469 0x3439 0x33ff 0x33ea 0x33e5 0x34c7 0x3463 0x3432 0x33fb 0x33eb 0x33e5 0x34bc 0x345f 0x342d 0x33fb 0x33ec 0x33e5 0x34b9 0x345c 0x3429 0x33fd 0x33ef 0x33e8 0x34b6 0x345a 0x3426 0x33ff 0x33f0 0x33ea 0x34ae 0x3455 0x3421 0x33fd 0x33ee 0x33e9 0x34a5 0x344f 0x341c 0x33fa 0x33eb 0x33e6 0x34a2 0x3449 0x3417 0x33f5 0x33e8 0x33e3 0x34a2 0x3444 0x3411 0x33ee 0x33e4 0x33e0 0x34a2 0x343e 0x340e 0x33eb 0x33e2 0x33df 0x34a6 0x3431 0x340e 0x33eb 0x33e2 0x33de 0x34ae 0x3424 0x340e 0x33eb 0x33e1 0x33de 0x34b8 0x341e 0x340e 0x33eb 0x33e1 0x33de 0x34c8 0x3419 0x340e 0x33eb 0x33e1 0x33de 0x34db 0x3418 0x340d 0x33ec 0x33e1 0x33de 0x34f1 0x3419 0x340d 0x33ed 0x33e2 0x33dd 0x350c 0x341a 0x340d 0x33ee 0x33e2 0x33dd 0x352f 0x341e 0x3408 0x33ef 0x33e2 0x33de 0x355b 0x3428 0x3401 0x33ef 0x33e2 0x33df 0x3587 0x3433 0x3401 0x33ef 0x33e2 0x33df 0x35b3 0x3440 0x3407 0x33ef 0x33e1 0x33de 0x35e4 0x344f 0x340c 0x33ee 0x33e1 0x33dd 0x361d 0x3460 0x3410 0x33eb 0x33e0 0x33de 0x365b 0x3473 0x3413 0x33e8 0x33e0 0x33de 0x369c 0x348b 0x3415 0x33ea 0x33e2 0x33de 0x36e0 0x34ab 0x3416 0x33eb 0x33e3 0x33e0 0x372f 0x34de 0x3417 0x33ea 0x33e2 0x33e0 0x3770 0x351c 0x3418 0x33ea 0x33e3 0x33e1 0x3746 0x3524 0x3410 0x33eb 0x33e1 0x33df 0x379b 0x356b 0x3414 0x33ea 0x33de 0x33dc 0x381a 0x35ed 0x3426 0x33ed 0x33e6 0x33e2 0x3861 0x3639 0x3431 0x33f3 0x33e7 0x33e7 0x38ac 0x3678 0x3440 0x33f8 0x33ea 0x33ea 0x38f5 0x36b7 0x344b 0x33fd 0x33f0 0x33ec 0x394c 0x370e 0x3459 0x3400 0x33ee 0x33e8 0x39bb 0x3753 0x3460 0x33fb 0x33e9 0x33e5 0x3a5b 0x37a8 0x3474 0x33ff 0x33e9 0x33e7 0x3bf0 0x3844 0x34b2 0x3408 0x33f0 0x33ea 0x3f63 0x397a 0x3520 0x3411 0x33f6 0x33f2 0x3f63 0x397a 0x3520 0x3411 0x33f6 0x33f2 0x3f63 0x397a 0x3520 0x3411 0x33f6 0x33f2>;
	};

	qcom,pc-temp-y4-lut {
		qcom,lut-col-legend = <0xfffffff6 0x00 0x0a 0x19 0x28 0x32>;
		qcom,lut-row-legend = <0x2710 0x2648 0x2580 0x24b8 0x23f0 0x2328 0x2260 0x2198 0x20d0 0x2008 0x1f40 0x1e78 0x1db0 0x1ce8 0x1c20 0x1b58 0x1a90 0x19c8 0x1900 0x1838 0x1770 0x16a8 0x15e0 0x1518 0x1450 0x1388 0x12c0 0x11f8 0x1130 0x1068 0xfa0 0xed8 0xe10 0xd48 0xc80 0xbb8 0xaf0 0xa28 0x960 0x898 0x7d0 0x708 0x640 0x578 0x4b0 0x3e8 0x384 0x320 0x2bc 0x258 0x1f4 0x190 0x12c 0xc8 0x64 0x00>;
		qcom,lut-data = <0x42e0 0x418a 0x40f8 0x406e 0x405d 0x404c 0x4318 0x41a3 0x4100 0x4070 0x4057 0x404d 0x4369 0x41d0 0x410a 0x4073 0x4053 0x404d 0x43bc 0x4203 0x4113 0x4076 0x4052 0x404e 0x43f9 0x422b 0x4119 0x4079 0x4051 0x404f 0x440a 0x4239 0x411b 0x407d 0x4051 0x4050 0x43ff 0x423b 0x4119 0x4082 0x4053 0x4052 0x43f5 0x423c 0x4117 0x4086 0x4055 0x4053 0x4403 0x4241 0x411a 0x4083 0x4057 0x4053 0x4430 0x424e 0x4124 0x407e 0x405a 0x4052 0x446f 0x4266 0x412d 0x407e 0x405d 0x4053 0x44de 0x42a1 0x4137 0x4087 0x4062 0x4056 0x451d 0x42dd 0x4148 0x4091 0x4067 0x405b 0x4433 0x4311 0x4188 0x409b 0x406c 0x405e 0x42e7 0x4337 0x41cb 0x40a7 0x4071 0x4063 0x42af 0x42ec 0x41c3 0x40b3 0x4077 0x4069 0x42a6 0x41ee 0x4196 0x40bf 0x407f 0x4072 0x429a 0x418b 0x4170 0x40d4 0x408c 0x407d 0x4284 0x4190 0x4152 0x4100 0x40a5 0x408d 0x4269 0x4195 0x4133 0x411a 0x40b5 0x4097 0x4249 0x4182 0x4106 0x40f5 0x40ad 0x4094 0x4227 0x4154 0x40d9 0x40b6 0x4099 0x408b 0x420d 0x4134 0x40c1 0x408f 0x4081 0x407c 0x41f7 0x411b 0x40b3 0x4071 0x4060 0x405e 0x41ed 0x4108 0x40aa 0x4066 0x4054 0x4052 0x41ec 0x40f8 0x40a5 0x4064 0x4054 0x4052 0x41ec 0x40ee 0x40a1 0x4064 0x4054 0x4052 0x41ec 0x40ee 0x409e 0x4065 0x4056 0x4054 0x41ed 0x40f3 0x409c 0x4068 0x405b 0x4058 0x41ee 0x40f8 0x4098 0x406b 0x4061 0x405d 0x41f0 0x40fe 0x4091 0x406f 0x4068 0x4064 0x41f1 0x4107 0x408c 0x4073 0x406f 0x406c 0x41ef 0x4121 0x4092 0x4076 0x4079 0x4077 0x41ec 0x4147 0x409a 0x4078 0x4082 0x4080 0x41ec 0x415a 0x409e 0x4077 0x407d 0x407c 0x41f0 0x4163 0x40a1 0x4071 0x406d 0x406e 0x41f6 0x416b 0x40a5 0x406c 0x4060 0x4062 0x4201 0x4173 0x40ae 0x4065 0x4054 0x4055 0x4210 0x4179 0x40b7 0x4062 0x404e 0x404e 0x421f 0x417e 0x40bd 0x4062 0x4052 0x4052 0x4230 0x4181 0x40c2 0x4063 0x4057 0x4057 0x4241 0x4185 0x40c7 0x4069 0x4059 0x4059 0x424e 0x418b 0x40c4 0x406a 0x4059 0x405a 0x421b 0x4179 0x40b5 0x405b 0x404c 0x404a 0x4218 0x4188 0x40bf 0x4057 0x4043 0x403e 0x4236 0x41b1 0x40d5 0x4069 0x4050 0x404f 0x424c 0x41d4 0x40f4 0x4075 0x405f 0x4068 0x4262 0x4208 0x412f 0x408c 0x407e 0x408b 0x4274 0x424a 0x4167 0x40b0 0x40ad 0x40ba 0x4288 0x4283 0x41b7 0x40d6 0x40aa 0x40a1 0x4298 0x429e 0x41b8 0x40a8 0x4067 0x4063 0x4292 0x4295 0x41b7 0x40a6 0x4068 0x4065 0x430a 0x4289 0x41e7 0x40cf 0x4078 0x4067 0x44b6 0x42cf 0x425c 0x410b 0x40a6 0x4093 0x44b6 0x42cf 0x425c 0x410b 0x40a6 0x4093 0x44b6 0x42cf 0x425c 0x410b 0x40a6 0x4093>;
	};

	qcom,pc-temp-y5-lut {
		qcom,lut-col-legend = <0xfffffff6 0x00 0x0a 0x19 0x28 0x32>;
		qcom,lut-row-legend = <0x2710 0x2648 0x2580 0x24b8 0x23f0 0x2328 0x2260 0x2198 0x20d0 0x2008 0x1f40 0x1e78 0x1db0 0x1ce8 0x1c20 0x1b58 0x1a90 0x19c8 0x1900 0x1838 0x1770 0x16a8 0x15e0 0x1518 0x1450 0x1388 0x12c0 0x11f8 0x1130 0x1068 0xfa0 0xed8 0xe10 0xd48 0xc80 0xbb8 0xaf0 0xa28 0x960 0x898 0x7d0 0x708 0x640 0x578 0x4b0 0x3e8 0x384 0x320 0x2bc 0x258 0x1f4 0x190 0x12c 0xc8 0x64 0x00>;
		qcom,lut-data = <0x2db9 0x3651 0x3b9c 0x46cd 0x4454 0x5b74 0x2da8 0x3798 0x3d8d 0x4327 0x44ea 0x5573 0x2dd7 0x3999 0x400f 0x3f99 0x4542 0x4e19 0x2e3a 0x3bb4 0x4280 0x3c55 0x456c 0x46d4 0x2ec6 0x3d48 0x4441 0x398f 0x457a 0x4111 0x2f75 0x3dbc 0x44b9 0x3773 0x455c 0x3e22 0x3098 0x3d87 0x4477 0x3591 0x4334 0x3c97 0x3170 0x3d54 0x43f5 0x348b 0x40b1 0x3bdd 0x30a6 0x4052 0x42a6 0x3732 0x3fa2 0x3e02 0x2edc 0x46b8 0x405d 0x3c31 0x3edc 0x422c 0x2f97 0x470f 0x3e71 0x3cb4 0x3db1 0x42b1 0x37b4 0x3f08 0x3c92 0x3a65 0x3bf8 0x40a1 0x3d05 0x39f2 0x3bc5 0x3934 0x3ab8 0x3e8c 0x3b24 0x40f7 0x3be4 0x3a31 0x39fd 0x3d2f 0x37a9 0x4a6a 0x3c37 0x3b49 0x398f 0x3bd8 0x34a4 0x4a90 0x3fb8 0x3a83 0x3984 0x39dd 0x3194 0x47a2 0x4916 0x3875 0x3981 0x3790 0x309f 0x46ac 0x4dc3 0x382b 0x398f 0x370f 0x31c5 0x49c4 0x4f74 0x3b25 0x3a47 0x384e 0x32da 0x4cd2 0x502b 0x3fcc 0x3ba5 0x3a58 0x3287 0x4d69 0x5020 0x49b2 0x429e 0x3e71 0x3196 0x4db8 0x4ffb 0x540b 0x4bdd 0x4386 0x30ab 0x4da2 0x4e4a 0x5213 0x4cc3 0x4607 0x2fb0 0x4c95 0x47ef 0x47b3 0x4b3d 0x47a8 0x2ee1 0x4ab1 0x44ff 0x4383 0x49c8 0x4819 0x2e3f 0x42b3 0x46a0 0x435b 0x48a8 0x472d 0x2dd1 0x38fe 0x48d2 0x434c 0x4794 0x45bd 0x2dc0 0x35b3 0x49fc 0x43c4 0x4656 0x4444 0x2dbc 0x33e6 0x4ae1 0x451f 0x452f 0x429d 0x2db7 0x3358 0x4bf1 0x4776 0x451e 0x4126 0x2dac 0x3344 0x4d5d 0x4c4b 0x462d 0x3fac 0x2da5 0x332c 0x4e0f 0x5071 0x4783 0x3f10 0x2e06 0x3208 0x46aa 0x532b 0x48eb 0x4176 0x2ec5 0x302d 0x3c91 0x5552 0x4a83 0x4557 0x2eec 0x300e 0x3cc9 0x5721 0x4c6e 0x47fd 0x2ed2 0x313c 0x41be 0x589c 0x4e8d 0x4a3e 0x2eaa 0x322c 0x45d9 0x575e 0x4f1b 0x4c4a 0x2e4f 0x32a2 0x491c 0x4bb5 0x4ec6 0x4e79 0x2df5 0x32e7 0x4aef 0x43f0 0x4e86 0x4fa1 0x2df8 0x325d 0x49f6 0x453f 0x4f92 0x4ed1 0x2e2d 0x312b 0x47be 0x4633 0x5095 0x4db1 0x2f1a 0x30f7 0x453d 0x42a6 0x4ca7 0x4d2f 0x2fb0 0x30bd 0x4330 0x424d 0x4ba4 0x4e9a 0x3012 0x316f 0x3b91 0x4849 0x4cc1 0x51a2 0x30ee 0x30d6 0x3a82 0x4396 0x41c8 0x42c0 0x312e 0x3238 0x3f93 0x3f90 0x47d3 0x4341 0x319d 0x338d 0x408c 0x454b 0x441f 0x4596 0x32f8 0x32f0 0x4255 0x47d4 0x42f7 0x42e7 0x336a 0x336a 0x4463 0x4842 0x452c 0x4216 0x33d1 0x37b0 0x465c 0x47cd 0x4210 0x3d82 0x340e 0x38fa 0x465b 0x4739 0x48b6 0x4264 0x3343 0x3782 0x3a93 0x4c09 0x4511 0x4434 0x2fe1 0x3366 0x349c 0x4ff9 0x5198 0x4547 0x2b1f 0x2f08 0x31ca 0x4d61 0x5625 0x5479 0x2b1f 0x2f08 0x31ca 0x4d61 0x5625 0x5479 0x2b1f 0x2f08 0x31ca 0x4d61 0x5625 0x5479>;
	};

	qcom,pc-temp-y6-lut {
		qcom,lut-col-legend = <0xfffffff6 0x00 0x0a 0x19 0x28 0x32>;
		qcom,lut-row-legend = <0x2710 0x2648 0x2580 0x24b8 0x23f0 0x2328 0x2260 0x2198 0x20d0 0x2008 0x1f40 0x1e78 0x1db0 0x1ce8 0x1c20 0x1b58 0x1a90 0x19c8 0x1900 0x1838 0x1770 0x16a8 0x15e0 0x1518 0x1450 0x1388 0x12c0 0x11f8 0x1130 0x1068 0xfa0 0xed8 0xe10 0xd48 0xc80 0xbb8 0xaf0 0xa28 0x960 0x898 0x7d0 0x708 0x640 0x578 0x4b0 0x3e8 0x384 0x320 0x2bc 0x258 0x1f4 0x190 0x12c 0xc8 0x64 0x00>;
		qcom,lut-data = <0x19eb 0x1630 0x14cb 0x1402 0x13d8 0x13d4 0x19cc 0x163d 0x14ce 0x1401 0x13d7 0x13d2 0x19ad 0x1644 0x14cf 0x1400 0x13d7 0x13d1 0x198d 0x1648 0x14cf 0x1400 0x13d8 0x13d0 0x196d 0x1649 0x14ce 0x1400 0x13d8 0x13cf 0x194d 0x1649 0x14cc 0x1400 0x13d8 0x13cf 0x192b 0x163e 0x14c8 0x1400 0x13d9 0x13d0 0x190a 0x1634 0x14c5 0x1400 0x13d9 0x13d1 0x18e4 0x1637 0x14c5 0x1402 0x13da 0x13d2 0x18bf 0x1640 0x14c5 0x1404 0x13db 0x13d3 0x18b9 0x1642 0x14c5 0x1407 0x13dd 0x13d5 0x18cc 0x1642 0x14c6 0x1408 0x13de 0x13d6 0x18d7 0x1641 0x14c7 0x140b 0x13e0 0x13d7 0x188a 0x1640 0x14d8 0x1411 0x13e1 0x13d8 0x1817 0x163f 0x14eb 0x1417 0x13e4 0x13da 0x17f7 0x1626 0x14e7 0x141a 0x13e6 0x13dc 0x17ea 0x15de 0x14d6 0x141c 0x13e9 0x13de 0x17e1 0x15c2 0x14c7 0x1420 0x13ee 0x13e1 0x17db 0x15c5 0x14bd 0x142e 0x13f7 0x13e8 0x17d5 0x15c7 0x14b2 0x1437 0x13fc 0x13ec 0x17cc 0x15bf 0x14a2 0x142b 0x13f9 0x13ea 0x17c4 0x15ad 0x1491 0x1417 0x13f1 0x13e5 0x17c2 0x15a5 0x1487 0x1408 0x13e7 0x13de 0x17c3 0x15a1 0x147f 0x13fb 0x13db 0x13d4 0x17c4 0x159e 0x147d 0x13f6 0x13d6 0x13d0 0x17cc 0x159a 0x147d 0x13f6 0x13d6 0x13cf 0x17da 0x1598 0x147d 0x13f5 0x13d6 0x13cf 0x17e9 0x1599 0x147e 0x13f6 0x13d6 0x13d0 0x17fb 0x15a1 0x147e 0x13f8 0x13d8 0x13d1 0x180f 0x15ab 0x147f 0x13fa 0x13da 0x13d3 0x1826 0x15b9 0x1481 0x13fc 0x13dc 0x13d4 0x1841 0x15c9 0x1483 0x13ff 0x13df 0x13d7 0x185f 0x15de 0x1483 0x1401 0x13e2 0x13db 0x1881 0x15f6 0x1484 0x1402 0x13e5 0x13de 0x18a5 0x1612 0x1487 0x1402 0x13e4 0x13dd 0x18cb 0x1632 0x1491 0x1401 0x13df 0x13d9 0x18f5 0x1656 0x149c 0x1400 0x13db 0x13d5 0x1925 0x1681 0x14a7 0x13fd 0x13d8 0x13d2 0x1958 0x16b0 0x14b3 0x13fb 0x13d6 0x13d0 0x198f 0x16e1 0x14bf 0x13fc 0x13d9 0x13d2 0x19c8 0x1716 0x14cb 0x13ff 0x13db 0x13d5 0x1a07 0x1757 0x14da 0x1401 0x13dc 0x13d6 0x1a3f 0x1799 0x14ed 0x1403 0x13dc 0x13d7 0x1a21 0x17a0 0x14e3 0x1400 0x13d8 0x13d1 0x1a63 0x17e6 0x1508 0x1400 0x13d4 0x13cc 0x1ac9 0x185f 0x153b 0x140a 0x13de 0x13d6 0x1b07 0x18ab 0x1565 0x1413 0x13e4 0x13e1 0x1b4b 0x18ee 0x1597 0x141e 0x13ef 0x13ed 0x1b8a 0x1933 0x15bb 0x142d 0x1400 0x13fd 0x1bd3 0x1988 0x15eb 0x143a 0x13fe 0x13f3 0x1c30 0x19ca 0x1606 0x142b 0x13e8 0x13df 0x1cae 0x1a12 0x1625 0x1433 0x13ea 0x13e2 0x1e34 0x1a8d 0x1694 0x144c 0x13f5 0x13e6 0x2197 0x1ba3 0x174a 0x146c 0x1408 0x13fb 0x2197 0x1ba3 0x174a 0x146c 0x1408 0x13fb 0x2197 0x1ba3 0x174a 0x146c 0x1408 0x13fb>;
	};
};
